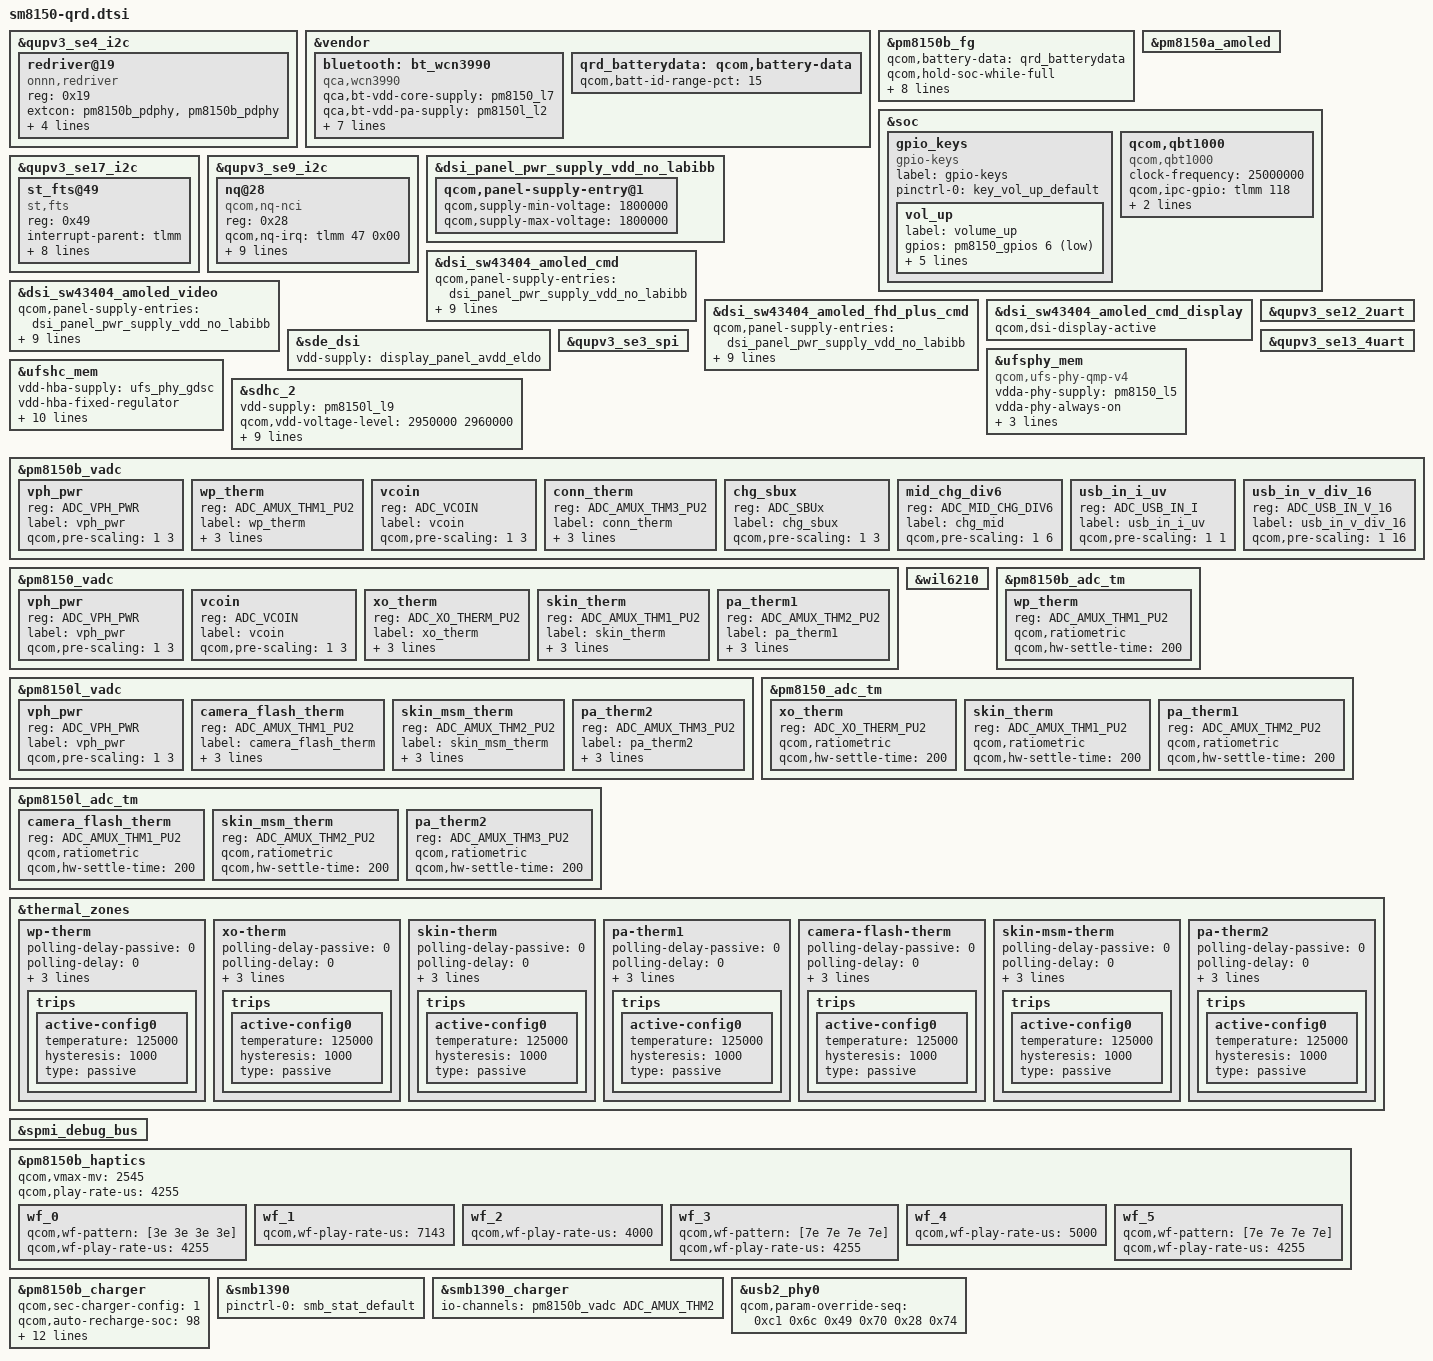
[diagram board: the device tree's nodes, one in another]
/* Copyright (c) 2017-2019, The Linux Foundation. All rights reserved.
 * Copyright (C) 2019 XiaoMi, Inc.
 *
 * This program is free software; you can redistribute it and/or modify
 * it under the terms of the GNU General Public License version 2 and
 * only version 2 as published by the Free Software Foundation.
 *
 * This program is distributed in the hope that it will be useful,
 * but WITHOUT ANY WARRANTY; without even the implied warranty of
 * MERCHANTABILITY or FITNESS FOR A PARTICULAR PURPOSE.  See the
 * GNU General Public License for more details.
 */

#include <dt-bindings/gpio/gpio.h>
#include <dt-bindings/input/input.h>

#include "sm8150-pmic-overlay.dtsi"
#include "sm8150-sde-display.dtsi"
#include "sm8150-camera-sensor-qrd.dtsi"
#include "sm8150-thermal-overlay.dtsi"

&qupv3_se4_i2c {
#include "smb1390.dtsi"
#include "smb1355.dtsi"
};

&vendor {
	bluetooth: bt_wcn3990 {
		compatible = "qca,wcn3990";
		qca,bt-vdd-core-supply = <&pm8150_l7>;
		qca,bt-vdd-pa-supply = <&pm8150l_l2>;
		qca,bt-vdd-ldo-supply = <&pm8150l_l11>;

		qca,bt-vdd-core-voltage-level = <1800000 1800000>;
		qca,bt-vdd-pa-voltage-level = <1304000 1304000>;
		qca,bt-vdd-ldo-voltage-level = <3312000 3312000>;

		qca,bt-vdd-core-current-level = <0>; /* LPM/PFM */
		qca,bt-vdd-pa-current-level = <0>; /* LPM/PFM */
		qca,bt-vdd-ldo-current-level = <0>; /* LPM/PFM */
	};

	qrd_batterydata: qcom,battery-data {
		qcom,batt-id-range-pct = <15>;
		#include "fg-gen4-batterydata-mlp466076-3250mah.dtsi"
	};
};

&pm8150b_fg {
	qcom,battery-data = <&qrd_batterydata>;
	qcom,hold-soc-while-full;
	qcom,linearize-soc;
	qcom,five-pin-battery;
	/* ESR fast calibration */
	qcom,fg-esr-timer-chg-fast = <0 7>;
	qcom,fg-esr-timer-dischg-fast = <0 7>;
	qcom,fg-esr-timer-chg-slow = <0 96>;
	qcom,fg-esr-timer-dischg-slow = <0 96>;
	qcom,fg-esr-cal-soc-thresh = <26 230>;
	qcom,fg-esr-cal-temp-thresh = <10 40>;
};

&pm8150a_amoled {
	status = "ok";
};

&soc {
	gpio_keys {
		compatible = "gpio-keys";
		label = "gpio-keys";

		pinctrl-names = "default";
		pinctrl-0 = <&key_vol_up_default>;

		vol_up {
			label = "volume_up";
			gpios = <&pm8150_gpios 6 GPIO_ACTIVE_LOW>;
			linux,input-type = <1>;
			linux,code = <KEY_VOLUMEUP>;
			gpio-key,wakeup;
			debounce-interval = <15>;
			linux,can-disable;
		};
	};

	qcom,qbt1000 {
		compatible = "qcom,qbt1000";
		clock-names = "core", "iface";
		clock-frequency = <25000000>;
		qcom,ipc-gpio = <&tlmm 118 0>;
		pinctrl-names = "default";
		pinctrl-0 = <&key_home_default>;
		qcom,finger-detect-gpio = <&pm8150_gpios 1 0>;
	};
};

&qupv3_se17_i2c {
	status = "ok";

	st_fts@49 {
		compatible = "st,fts";
		reg = <0x49>;
		interrupt-parent = <&tlmm>;
		interrupts = <122 0x2008>;
		vdd-supply = <&pm8150_s4>;
		avdd-supply = <&pm8150_l17>;
		pinctrl-names = "pmx_ts_active", "pmx_ts_suspend";
		pinctrl-0 = <&ts_active>;
		pinctrl-1 = <&ts_int_suspend &ts_reset_suspend>;
		st,irq-gpio = <&tlmm 122 0x2008>;
		//st,reset-gpio = <&tlmm 54 0x00>;
		st,regulator_dvdd = "vdd";
		st,regulator_avdd = "avdd";
	};
};

&qupv3_se9_i2c {
	status = "ok";
	nq@28 {
		compatible = "qcom,nq-nci";
		reg = <0x28>;
		qcom,nq-irq = <&tlmm 47 0x00>;
		qcom,nq-ven = <&tlmm 41 0x00>;
		qcom,nq-firm = <&tlmm 48 0x00>;
		qcom,nq-clkreq = <&tlmm 113 0x00>;
		interrupt-parent = <&tlmm>;
		interrupts = <47 0>;
		interrupt-names = "nfc_irq";
		pinctrl-names = "nfc_active", "nfc_suspend";
		pinctrl-0 = <&nfc_int_active &nfc_enable_active
					&nfc_clk_req_active>;
		pinctrl-1 = <&nfc_int_suspend &nfc_enable_suspend
					&nfc_clk_req_suspend>;
	};
};

&dsi_panel_pwr_supply_vdd_no_labibb {
	qcom,panel-supply-entry@1 {
		qcom,supply-min-voltage = <1800000>;
		qcom,supply-max-voltage = <1800000>;
	};
};

&dsi_sw43404_amoled_cmd {
	qcom,panel-supply-entries = <&dsi_panel_pwr_supply_vdd_no_labibb>;
	qcom,mdss-dsi-bl-pmic-control-type = "bl_ctrl_dcs";
	qcom,mdss-dsi-bl-min-level = <1>;
	qcom,mdss-dsi-bl-max-level = <1023>;
	qcom,mdss-brightness-max-level = <255>;
	qcom,mdss-dsi-mode-sel-gpio-state = "single_port";
	qcom,panel-mode-gpio = <&tlmm 7 0>;
	qcom,platform-te-gpio = <&tlmm 8 0>;
	qcom,platform-reset-gpio = <&tlmm 6 0>;
};

&dsi_sw43404_amoled_video {
	qcom,panel-supply-entries = <&dsi_panel_pwr_supply_vdd_no_labibb>;
	qcom,mdss-dsi-bl-pmic-control-type = "bl_ctrl_dcs";
	qcom,mdss-dsi-bl-min-level = <1>;
	qcom,mdss-dsi-bl-max-level = <1023>;
	qcom,mdss-brightness-max-level = <255>;
	qcom,mdss-dsi-mode-sel-gpio-state = "single_port";
	qcom,panel-mode-gpio = <&tlmm 7 0>;
	qcom,platform-te-gpio = <&tlmm 8 0>;
	qcom,platform-reset-gpio = <&tlmm 6 0>;
};

&dsi_sw43404_amoled_fhd_plus_cmd {
	qcom,panel-supply-entries = <&dsi_panel_pwr_supply_vdd_no_labibb>;
	qcom,mdss-dsi-bl-pmic-control-type = "bl_ctrl_dcs";
	qcom,mdss-dsi-bl-min-level = <1>;
	qcom,mdss-dsi-bl-max-level = <1023>;
	qcom,mdss-brightness-max-level = <255>;
	qcom,mdss-dsi-mode-sel-gpio-state = "single_port";
	qcom,panel-mode-gpio = <&tlmm 7 0>;
	qcom,platform-te-gpio = <&tlmm 8 0>;
	qcom,platform-reset-gpio = <&tlmm 6 0>;
};

&dsi_sw43404_amoled_cmd_display {
	qcom,dsi-display-active;
};

&sde_dsi {
	vdd-supply = <&display_panel_avdd_eldo>;
};

&qupv3_se12_2uart {
	status = "ok";
};

&qupv3_se13_4uart {
	status = "ok";
};

&qupv3_se3_spi {
	status = "ok";
};

&qupv3_se4_i2c {
	status = "ok";
	redriver@19 {
		compatible = "onnn,redriver";
		reg = <0x19>;
		extcon = <&pm8150b_pdphy>, <&pm8150b_pdphy>;
		eq = /bits/ 8 <
				/* Parameters for USB */
				0x4 0x4 0x4 0x4
				/* Parameters for DP */
				0x6 0x4 0x4 0x6>;
		flat-gain = /bits/ 8 <
				/* Parameters for USB */
				0x3 0x1 0x1 0x3
				/* Parameters for DP */
				0x2 0x1 0x1 0x2>;
		output-comp = /bits/ 8 <
				/* Parameters for USB */
				0x3 0x3 0x3 0x3
				/* Parameters for DP */
				0x3 0x3 0x3 0x3>;
		loss-match = /bits/ 8 <
				/* Parameters for USB */
				0x1 0x3 0x3 0x1
				/* Parameters for DP */
				0x3 0x3 0x3 0x3>;
	};
};

&ufsphy_mem {
	compatible = "qcom,ufs-phy-qmp-v4";

	vdda-phy-supply = <&pm8150_l5>;
	vdda-phy-always-on;
	vdda-pll-supply = <&pm8150l_l3>;
	vdda-phy-max-microamp = <90200>;
	vdda-pll-max-microamp = <19000>;

	status = "ok";
};

&ufshc_mem {
	vdd-hba-supply = <&ufs_phy_gdsc>;
	vdd-hba-fixed-regulator;
	vcc-supply = <&pm8150_l10>;
	vcc-voltage-level = <2504000 2950000>;
	vcc-low-voltage-sup;
	vccq-supply = <&pm8150_l9>;
	vccq2-supply = <&pm8150_s4>;
	vcc-max-microamp = <750000>;
	vccq-max-microamp = <700000>;
	vccq2-max-microamp = <750000>;

	qcom,vddp-ref-clk-supply = <&pm8150_l9>;
	qcom,vddp-ref-clk-max-microamp = <100>;

	status = "ok";
};

&sdhc_2 {
	vdd-supply = <&pm8150l_l9>;
	qcom,vdd-voltage-level = <2950000 2960000>;
	qcom,vdd-current-level = <200 800000>;

	vdd-io-supply = <&pm8150l_l6>;
	qcom,vdd-io-voltage-level = <1808000 2960000>;
	qcom,vdd-io-current-level = <200 22000>;

	pinctrl-names = "active", "sleep";
	pinctrl-0 = <&sdc2_clk_on  &sdc2_cmd_on &sdc2_data_on &storage_cd>;
	pinctrl-1 = <&sdc2_clk_off &sdc2_cmd_off &sdc2_data_off &storage_cd>;

	cd-gpios = <&tlmm 96 GPIO_ACTIVE_HIGH>;

	status = "ok";
};

&pm8150b_vadc {
	vph_pwr {
		reg = <ADC_VPH_PWR>;
		label = "vph_pwr";
		qcom,pre-scaling = <1 3>;
	};

	wp_therm {
		reg = <ADC_AMUX_THM1_PU2>;
		label = "wp_therm";
		qcom,ratiometric;
		qcom,hw-settle-time = <200>;
		qcom,pre-scaling = <1 1>;
	};

	vcoin {
		reg = <ADC_VCOIN>;
		label = "vcoin";
		qcom,pre-scaling = <1 3>;
	};

	conn_therm {
		reg = <ADC_AMUX_THM3_PU2>;
		label = "conn_therm";
		qcom,ratiometric;
		qcom,hw-settle-time = <200>;
		qcom,pre-scaling = <1 1>;
	};

	chg_sbux {
		reg = <ADC_SBUx>;
		label = "chg_sbux";
		qcom,pre-scaling = <1 3>;
	};

	mid_chg_div6 {
		reg = <ADC_MID_CHG_DIV6>;
		label = "chg_mid";
		qcom,pre-scaling = <1 6>;
	};

	usb_in_i_uv {
		reg = <ADC_USB_IN_I>;
		label = "usb_in_i_uv";
		qcom,pre-scaling = <1 1>;
	};

	usb_in_v_div_16 {
		reg = <ADC_USB_IN_V_16>;
		label = "usb_in_v_div_16";
		qcom,pre-scaling = <1 16>;
	};
};

&pm8150_vadc {
	vph_pwr {
		reg = <ADC_VPH_PWR>;
		label = "vph_pwr";
		qcom,pre-scaling = <1 3>;
	};

	vcoin {
		reg = <ADC_VCOIN>;
		label = "vcoin";
		qcom,pre-scaling = <1 3>;
	};

	xo_therm {
		reg = <ADC_XO_THERM_PU2>;
		label = "xo_therm";
		qcom,ratiometric;
		qcom,hw-settle-time = <200>;
		qcom,pre-scaling = <1 1>;
	};

	skin_therm {
		reg = <ADC_AMUX_THM1_PU2>;
		label = "skin_therm";
		qcom,ratiometric;
		qcom,hw-settle-time = <200>;
		qcom,pre-scaling = <1 1>;
	};

	pa_therm1 {
		reg = <ADC_AMUX_THM2_PU2>;
		label = "pa_therm1";
		qcom,ratiometric;
		qcom,hw-settle-time = <200>;
		qcom,pre-scaling = <1 1>;
	};
};

&pm8150l_vadc {
	vph_pwr {
		reg = <ADC_VPH_PWR>;
		label = "vph_pwr";
		qcom,pre-scaling = <1 3>;
	};

	camera_flash_therm {
		reg = <ADC_AMUX_THM1_PU2>;
		label = "camera_flash_therm";
		qcom,ratiometric;
		qcom,hw-settle-time = <200>;
		qcom,pre-scaling = <1 1>;
	};

	skin_msm_therm {
		reg = <ADC_AMUX_THM2_PU2>;
		label = "skin_msm_therm";
		qcom,ratiometric;
		qcom,hw-settle-time = <200>;
		qcom,pre-scaling = <1 1>;
	};

	pa_therm2 {
		reg = <ADC_AMUX_THM3_PU2>;
		label = "pa_therm2";
		qcom,ratiometric;
		qcom,hw-settle-time = <200>;
		qcom,pre-scaling = <1 1>;
	};
};

&wil6210 {
	status = "ok";
};

&pm8150b_adc_tm {
	wp_therm {
		reg = <ADC_AMUX_THM1_PU2>;
		qcom,ratiometric;
		qcom,hw-settle-time = <200>;
	};
};

&pm8150_adc_tm {
	xo_therm {
		reg = <ADC_XO_THERM_PU2>;
		qcom,ratiometric;
		qcom,hw-settle-time = <200>;
	};

	skin_therm {
		reg = <ADC_AMUX_THM1_PU2>;
		qcom,ratiometric;
		qcom,hw-settle-time = <200>;
	};

	pa_therm1 {
		reg = <ADC_AMUX_THM2_PU2>;
		qcom,ratiometric;
		qcom,hw-settle-time = <200>;
	};
};

&pm8150l_adc_tm {
	camera_flash_therm {
		reg = <ADC_AMUX_THM1_PU2>;
		qcom,ratiometric;
		qcom,hw-settle-time = <200>;
	};

	skin_msm_therm {
		reg = <ADC_AMUX_THM2_PU2>;
		qcom,ratiometric;
		qcom,hw-settle-time = <200>;
	};

	pa_therm2 {
		reg = <ADC_AMUX_THM3_PU2>;
		qcom,ratiometric;
		qcom,hw-settle-time = <200>;
	};
};

&thermal_zones {
	wp-therm {
		polling-delay-passive = <0>;
		polling-delay = <0>;
		thermal-governor = "user_space";
		thermal-sensors = <&pm8150b_adc_tm ADC_AMUX_THM1_PU2>;
		trips {
			active-config0 {
				temperature = <125000>;
				hysteresis = <1000>;
				type = "passive";
			};
		};
	};

	xo-therm {
		polling-delay-passive = <0>;
		polling-delay = <0>;
		thermal-governor = "user_space";
		thermal-sensors = <&pm8150_adc_tm ADC_XO_THERM_PU2>;
		trips {
			active-config0 {
				temperature = <125000>;
				hysteresis = <1000>;
				type = "passive";
			};
		};
	};

	skin-therm {
		polling-delay-passive = <0>;
		polling-delay = <0>;
		thermal-governor = "user_space";
		thermal-sensors = <&pm8150_adc_tm ADC_AMUX_THM1_PU2>;
		trips {
			active-config0 {
				temperature = <125000>;
				hysteresis = <1000>;
				type = "passive";
			};
		};
	};

	pa-therm1 {
		polling-delay-passive = <0>;
		polling-delay = <0>;
		thermal-governor = "user_space";
		thermal-sensors = <&pm8150_adc_tm ADC_AMUX_THM2_PU2>;
		trips {
			active-config0 {
				temperature = <125000>;
				hysteresis = <1000>;
				type = "passive";
			};
		};
	};

	camera-flash-therm {
		polling-delay-passive = <0>;
		polling-delay = <0>;
		thermal-governor = "user_space";
		thermal-sensors = <&pm8150l_adc_tm ADC_AMUX_THM1_PU2>;
		trips {
			active-config0 {
				temperature = <125000>;
				hysteresis = <1000>;
				type = "passive";
			};
		};
	};

	skin-msm-therm {
		polling-delay-passive = <0>;
		polling-delay = <0>;
		thermal-governor = "user_space";
		thermal-sensors = <&pm8150l_adc_tm ADC_AMUX_THM2_PU2>;
		trips {
			active-config0 {
				temperature = <125000>;
				hysteresis = <1000>;
				type = "passive";
			};
		};
	};

	pa-therm2 {
		polling-delay-passive = <0>;
		polling-delay = <0>;
		thermal-governor = "user_space";
		thermal-sensors = <&pm8150l_adc_tm ADC_AMUX_THM3_PU2>;
		trips {
			active-config0 {
				temperature = <125000>;
				hysteresis = <1000>;
				type = "passive";
			};
		};
	};
};

&spmi_debug_bus {
	status = "ok";
};

&pm8150b_haptics {
	qcom,vmax-mv = <2545>;
	qcom,play-rate-us = <4255>;
	wf_0 {
		/* CLICK */
		qcom,wf-pattern = [3e 3e 3e 3e];
		qcom,wf-play-rate-us = <4255>;
	};
	wf_1 {
		/* DOUBLE CLICK */
		qcom,wf-play-rate-us = <7143>;
	};
	wf_2 {
		/* TICK */
		qcom,wf-play-rate-us = <4000>;
	};
	wf_3 {
		/* THUD */
		qcom,wf-pattern = [7e 7e 7e 7e];
		qcom,wf-play-rate-us = <4255>;
	};
	wf_4 {
		/* POP */
		qcom,wf-play-rate-us = <5000>;
	};
	wf_5 {
		/* HEAVY CLICK */
		qcom,wf-pattern = [7e 7e 7e 7e];
		qcom,wf-play-rate-us = <4255>;
	};
};

&pm8150b_charger {
	qcom,sec-charger-config = <1>;
	qcom,auto-recharge-soc = <98>;
	io-channels = <&pm8150b_vadc ADC_MID_CHG_DIV6>,
		      <&pm8150b_vadc ADC_USB_IN_I>,
		      <&pm8150b_vadc ADC_SBUx>,
		      <&pm8150b_vadc ADC_VPH_PWR>,
		      <&pm8150b_vadc ADC_CHG_TEMP>,
		      <&pm8150b_vadc ADC_USB_IN_V_16>;
	io-channel-names = "mid_voltage",
			   "usb_in_current",
			   "sbux_res",
			   "vph_voltage",
			   "chg_temp",
			   "usb_in_voltage";
	qcom,battery-data = <&qrd_batterydata>;
	qcom,sw-jeita-enable;
	qcom,wd-bark-time-secs = <16>;
	qcom,suspend-input-on-debug-batt;
	qcom,thermal-mitigation = <4875000 4000000 3500000
				3000000 2500000 2000000
				1500000 1000000 500000>;
};

&smb1390 {
	pinctrl-names = "default";
	pinctrl-0 = <&smb_stat_default>;
	status = "ok";
};

&smb1390_charger {
	io-channels = <&pm8150b_vadc ADC_AMUX_THM2>;
	io-channel-names = "cp_die_temp";
	status = "ok";
};

&usb2_phy0 {
	/*
	 * update SQRXTUNE0 to appropriate value if analog
	 * audio switch is installed.
	 * otherwise use power on default(i.e 0x3)
	 */
	qcom,param-override-seq =
		<0xc1 0x6c
		0x49 0x70
		0x28 0x74>;
};
